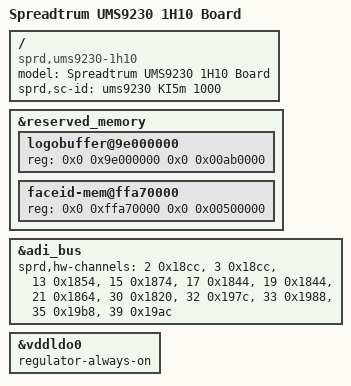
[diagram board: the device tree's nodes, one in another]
// SPDX-License-Identifier: (GPL-2.0+ OR MIT)
/dts-v1/;
/plugin/;

/ {
	model = "Spreadtrum UMS9230 1H10 Board";
	compatible = "sprd,ums9230-1h10";
	sprd,sc-id = "ums9230 KI5m 1000";
};

&reserved_memory {
	#address-cells = <2>;
	#size-cells = <2>;

	logobuffer@9e000000 {
		reg = <0x0 0x9e000000 0x0 0x00ab0000>;
	};

	faceid-mem@ffa70000 {
		reg = <0x0 0xffa70000 0x0 0x00500000>;
	};
};

&adi_bus {
	/* SC2730 hardware channels from the V218 slot-A overlay. */
	sprd,hw-channels = <2 0x18cc>, <3 0x18cc>, <13 0x1854>, <15 0x1874>,
			   <17 0x1844>, <19 0x1844>, <21 0x1864>, <30 0x1820>,
			   <32 0x197c>, <33 0x1988>, <35 0x19b8>, <39 0x19ac>;
};

&vddldo0 {
	regulator-always-on;
};
